# NPCX490M register map
File version: 1.0
Registers are 8-bit, read-write, reset 0x0 unless marked. A register's access mark holds for its fields unless they carry their own. Offsets are from the block's base; [hi:lo] are bit positions; {n}, {i} and the like mark numbered series; 'fields as' and 'values as' point back to an identical list.

## I3C1
Base 0x400F0000
Same registers: I3C2 0x400F2000, I3C3 0x400F4000
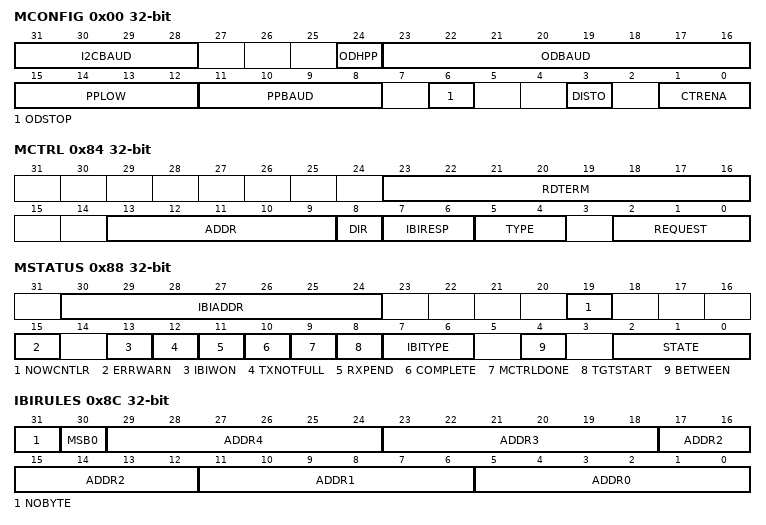
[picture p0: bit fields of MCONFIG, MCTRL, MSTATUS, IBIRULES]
0x00 MCONFIG 32-bit (reset mask 0xFF) — Controller Configuration
  [31:28] I2CBAUD — I2C Baud Rate
  [24] ODHPP — Open-Drain High Period
  [23:16] ODBAUD — Open-Drain Baud Rate
  [15:12] PPLOW — Push-Pull Low Period
  [11:8] PPBAUD — Push-Pull Baud Rate
  [6] ODSTOP — Open-Drain Stop
  [3] DISTO — Disable Timeout Error
  [1:0] CTRENA — Controller Device Enable.
0x84 MCTRL 32-bit (reset mask 0xFF) — Controller Control Register
  [23:16] RDTERM — Read Termination Counter
  [13:9] ADDR — Address
  [8] DIR — Transfer Direction
  [7:6] IBIRESP — IBI Response
  [5:4] TYPE — Operation Type
  [2:0] REQUEST — Bus Operation Request
0x88 MSTATUS 32-bit (reset mask 0xFF) — Controller Status Register
  [30:24] IBIADDR — IBI Address
  [19] NOWCNTLR — I3CI Now Bus Controller
  [15] ERRWARN — Error/Warning
  [13] IBIWON — IBI Arbitration Won
  [12] TXNOTFULL — Transmit Buffer Not Full
  [11] RXPEND — Receive Buffer Pending
  [10] COMPLETE — Message Completed
  [9] MCTRLDONE
  [8] TGTSTART — Target START Detected
  [7:6] IBITYPE
  [4] BETWEEN — Between Messages
  [2:0] STATE — Current Working State
0x8C IBIRULES 32-bit (reset mask 0xFF) — IBI Registry and Rules Register
  [31] NOBYTE — No Mandatory Byte
  [30] MSB0 — MSb is 0
  [6n+5:6n] ADDR{n} (n=0..4) — Target {n} Dynamic Address
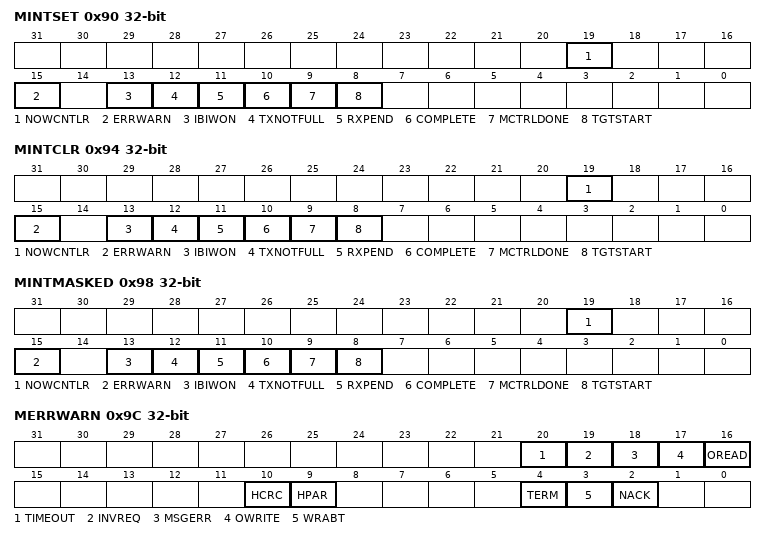
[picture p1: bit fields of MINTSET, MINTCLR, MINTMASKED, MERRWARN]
0x90 MINTSET 32-bit (reset mask 0xFF) — Controller Interrupt Enable Set Register
  [19] NOWCNTLR — I3CI Now Bus Controller
  [15] ERRWARN — Error/Warning
  [13] IBIWON — IBI Arbitration Won
  [12] TXNOTFULL — Transmit Buffer Not Full
  [11] RXPEND — Receive Buffer Pending
  [10] COMPLETE — Message Completed
  [9] MCTRLDONE
  [8] TGTSTART — Target START Detected
0x94 MINTCLR 32-bit (reset mask 0xFF) — Controller Interrupt Enable Clear Register
  fields as MINTSET
0x98 MINTMASKED 32-bit (reset mask 0xFF) — Controller Interrupt Masked Register
  fields as MINTSET
0x9C MERRWARN 32-bit (reset mask 0xFF) — Controller Error and Warning Register
  [20] TIMEOUT
  [19] INVREQ
  [18] MSGERR
  [17] OWRITE
  [16] OREAD
  [10] HCRC — HDR-DDR CRC Error
  [9] HPAR — HDR Parity Error
  [4] TERM — Terminated
  [3] WRABT — Write Aborted
  [2] NACK — Address NACKed
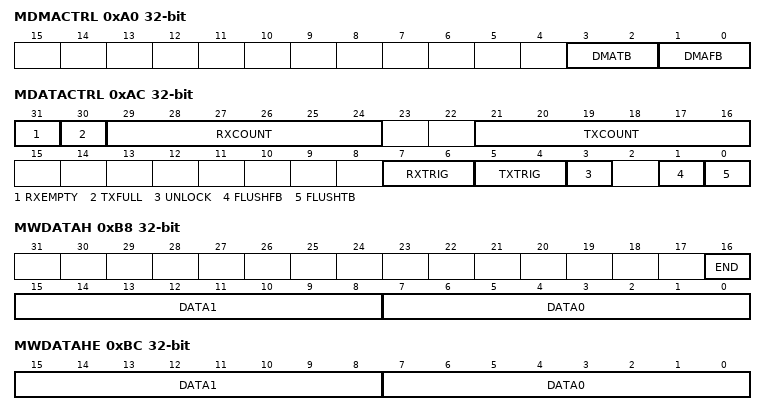
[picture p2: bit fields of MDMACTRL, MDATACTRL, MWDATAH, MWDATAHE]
0xA0 MDMACTRL 32-bit — Controller DMA Control Register
  [3:2] DMATB — DMA to Bus
  [1:0] DMAFB — DMA from Bus
0xAC MDATACTRL 32-bit (reset mask 0xFF) — Controller Data Control Register
  [31] RXEMPTY — Receive Buffer Empty
  [30] TXFULL — Transmit Buffer Full
  [29:24] RXCOUNT — Receive Count
  [21:16] TXCOUNT — Transmit Count
  [7:6] RXTRIG — Receive Trigger
  [5:4] TXTRIG — Transmit Trigger
  [3] UNLOCK
  [1] FLUSHFB — Flush From-Bus Buffer
  [0] FLUSHTB — Flush To-Bus Buffer
0xB4 MWDATABE 32-bit — Controller Write Byte Data as End Register
  [7:0] DATA — Data Byte
0xB8 MWDATAH 32-bit (reset mask 0xFF) — Controller Write Half-Word Data Register
  [16] END — End of Data
  [15:8] DATA1 — Second Data Byte
  [7:0] DATA0 — First Data Byte
0xBC MWDATAHE 32-bit (reset mask 0xFF) — Controller Write Half-Word Data as End Register
  [15:8] DATA1 — Second Data Byte
  [7:0] DATA0 — First Data Byte
0xC0 MRDATAB 32-bit — Controller Read Byte Data Register
  [7:0] DATA — Data Byte
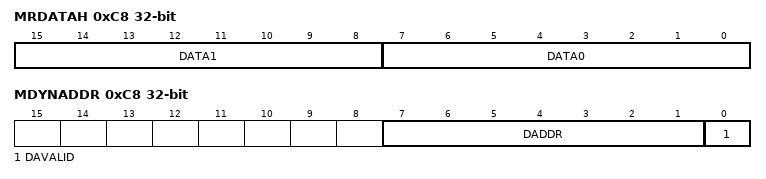
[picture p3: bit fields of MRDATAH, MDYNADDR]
0xC8 MRDATAH 32-bit (reset mask 0xFF) — Controller Read Half-Word Data Register
  [15:8] DATA1 — Second Data Byte
  [7:0] DATA0 — First Data Byte
0xC8 MDYNADDR 32-bit — Controller Dynamic Address Register
  [7:1] DADDR — Dynamic Address
  [0] DAVALID — Address Valid
0xD8 MWMSG_DDR 32-bit (reset mask 0xFF) — Start or Continue DDR Message Register
  [15:0] DATA — Data for HDR-DDR Writes
0xDC MRMSG_DDR 32-bit (reset mask 0xFF) — Read DDR Message Register
  [15:0] DATA — Read Data

## ITIM32_1
Base 0x400B0000
Same registers: ITIM32_2 0x400B2000, ITIM32_3 0x400B4000, ITIM32_4 0x400B6000, ITIM32_5 0x400B8000, ITIM32_6 0x400BA000
0x01 ITPRE32n — Internal Timer Prescaler Register (ITPRE32n)
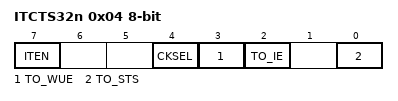
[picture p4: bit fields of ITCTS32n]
0x04 ITCTS32n — Internal Timer Control and Status Register (ITCTS32n)
  [7] ITEN — ITIM32 Module Enable
  [4] CKSEL — Input Clock Select
  [3] TO_WUE — Timeout Wake-Up Enable
  [2] TO_IE — Timeout Interrupt Enable
  [0] TO_STS — Timeout Status
0x08 ITCNT32n 32-bit (reset mask 0xFF) — Internal 32-Bit Timer Counter Register (ITCNT32n)
